# STM32F407 register map
File version: 1.7
CPU: CM4 r0p1, little endian, MPU, FPU, 4 interrupt priority bits
Registers are 32-bit, read-write, reset 0x0 unless marked. A register's access mark holds for its fields unless they carry their own. Offsets are from the block's base; [hi:lo] are bit positions; {n}, {i} and the like mark numbered series.

## OTG_FS_PWRCLK — USB on the go full speed
Base 0x50000E00
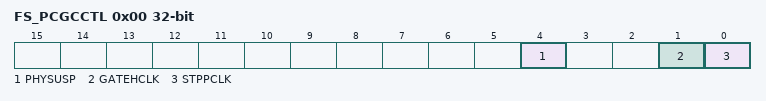
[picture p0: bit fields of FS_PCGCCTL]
0x00 FS_PCGCCTL — OTG_FS power and clock gating control register
  [4] PHYSUSP — PHY Suspended
  [1] GATEHCLK
  [0] STPPCLK — Stop PHY clock

## FLASH
Base 0x40023C00
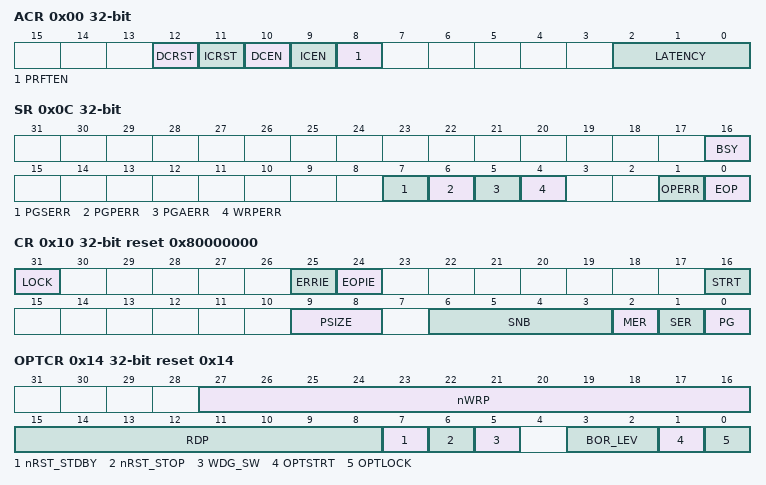
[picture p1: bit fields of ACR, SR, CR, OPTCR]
0x00 ACR access per field — Flash access control register
  [12] DCRST rw — Data cache reset
  [11] ICRST wo — Instruction cache reset
  [10] DCEN rw — Data cache enable
  [9] ICEN rw — Instruction cache enable
  [8] PRFTEN rw — Prefetch enable
  [2:0] LATENCY rw
0x04 KEYR wo — Flash key register
  [31:0] KEY — FPEC key
0x08 OPTKEYR wo — Flash option key register
  [31:0] OPTKEY — Option byte key
0x0C SR access per field — Status register
  [16] BSY ro — Busy
  [7] PGSERR rw — Programming sequence error
  [6] PGPERR rw — Programming parallelism error
  [5] PGAERR rw — Programming alignment error
  [4] WRPERR rw — Write protection error
  [1] OPERR rw — Operation error
  [0] EOP rw — End of operation
0x10 CR reset 0x80000000 — Control register
  [31] LOCK
  [25] ERRIE — Error interrupt enable
  [24] EOPIE — End of operation interrupt enable
  [16] STRT — Start
  [9:8] PSIZE — Program size
  [6:3] SNB — Sector number
  [2] MER — Mass Erase
  [1] SER — Sector Erase
  [0] PG — Programming
0x14 OPTCR reset 0x14 — Flash option control register
  [27:16] nWRP — Not write protect
  [15:8] RDP — Read protect
  [7] nRST_STDBY — nRST_STDBY User option bytes
  [6] nRST_STOP — nRST_STOP User option bytes
  [5] WDG_SW — WDG_SW User option bytes
  [3:2] BOR_LEV — BOR reset Level
  [1] OPTSTRT — Option start
  [0] OPTLOCK — Option lock

## EXTI — External interrupt/event controller
Base 0x40013C00
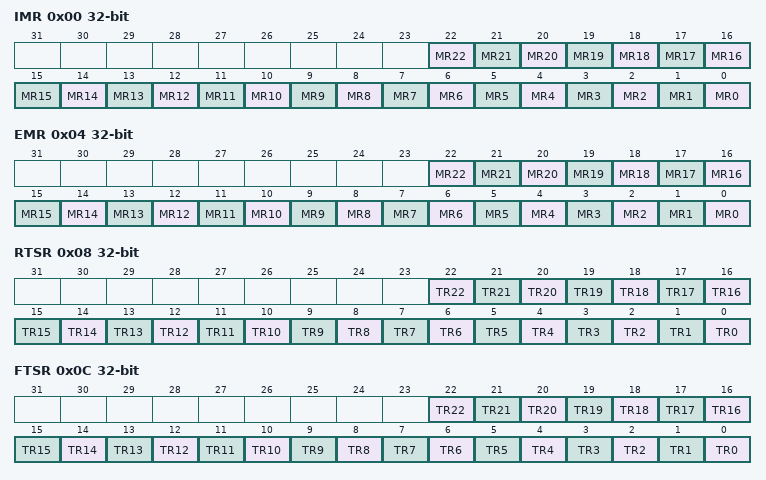
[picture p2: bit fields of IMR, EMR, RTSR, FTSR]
0x00 IMR — Interrupt mask register (EXTI_IMR)
  [n] MR{n} (n=0..22) — Interrupt Mask on line {n}
0x04 EMR — Event mask register (EXTI_EMR)
  [n] MR{n} (n=0..22) — Event Mask on line {n}
0x08 RTSR — Rising Trigger selection register (EXTI_RTSR)
  [n] TR{n} (n=0..22) — Rising trigger event configuration of line {n}
0x0C FTSR — Falling Trigger selection register (EXTI_FTSR)
  [n] TR{n} (n=0..22) — Falling trigger event configuration of line {n}
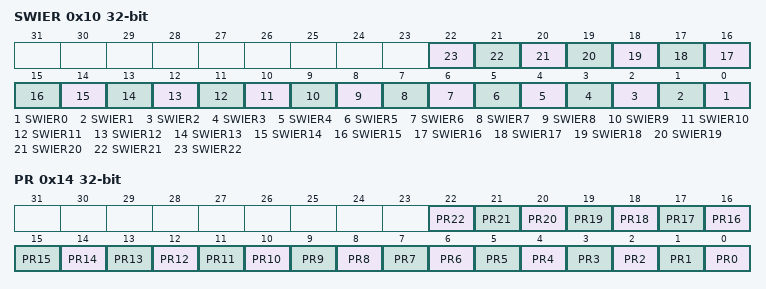
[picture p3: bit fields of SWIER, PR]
0x10 SWIER — Software interrupt event register (EXTI_SWIER)
  [n] SWIER{n} (n=0..22) — Software Interrupt on line {n}
0x14 PR — Pending register (EXTI_PR)
  [n] PR{n} (n=0..22) — Pending bit {n}

## OTG_HS_PWRCLK — USB on the go high speed
Base 0x40040E00
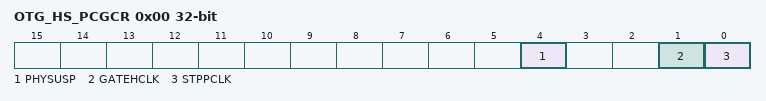
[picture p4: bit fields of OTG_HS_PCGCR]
0x00 OTG_HS_PCGCR — Power and clock gating control register
  [4] PHYSUSP — PHY suspended
  [1] GATEHCLK
  [0] STPPCLK — Stop PHY clock

## HASH — Hash processor
Base 0x50060400
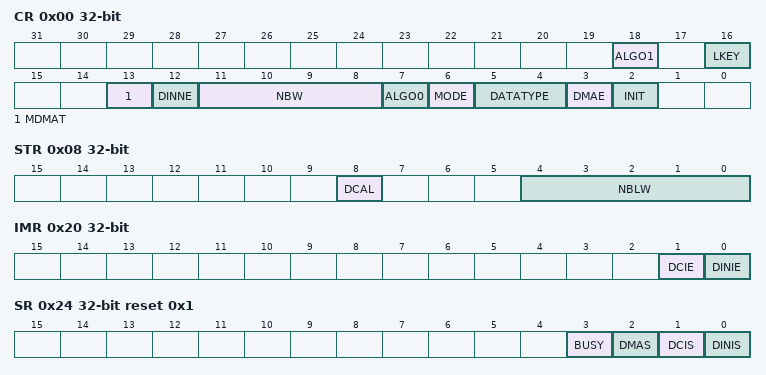
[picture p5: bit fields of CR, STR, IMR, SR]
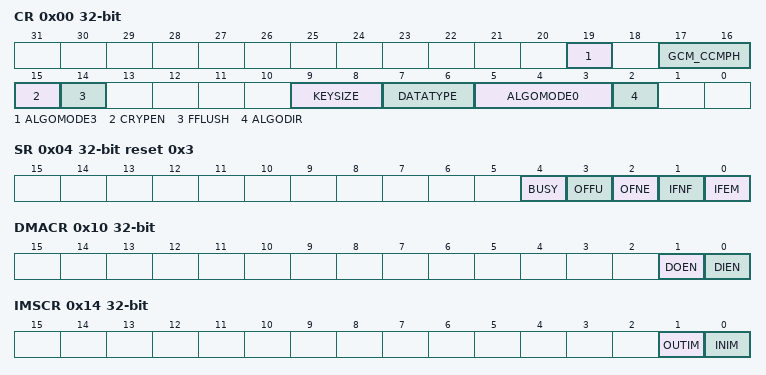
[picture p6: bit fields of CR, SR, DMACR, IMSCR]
0x00 CR access per field — control register
  [18] ALGO1 rw — ALGO
  [16] LKEY rw — Long key selection
  [13] MDMAT rw — Multiple DMA Transfers
  [12] DINNE ro — DIN not empty
  [11:8] NBW ro — Number of words already pushed
  [7] ALGO0 rw — Algorithm selection
  [6] MODE rw — Mode selection
  [5:4] DATATYPE rw — Data type selection
  [3] DMAE rw — DMA enable
  [2] INIT wo — Initialize message digest calculation
0x04 DIN — data input register
  [31:0] DATAIN — Data input
0x08 STR access per field — start register
  [8] DCAL wo — Digest calculation
  [4:0] NBLW rw — Number of valid bits in the last word of the message
{0xC+4i} HR{i} ro (i=0..4) — digest registers
  [31:0] H{i}
0x20 IMR — interrupt enable register
  [1] DCIE — Digest calculation completion interrupt enable
  [0] DINIE — Data input interrupt enable
0x24 SR access per field reset 0x1 — status register
  [3] BUSY ro — Busy bit
  [2] DMAS ro — DMA Status
  [1] DCIS rw — Digest calculation completion interrupt status
  [0] DINIS rw — Data input interrupt status
{0xF8+4i} CSR{i} (i=0..53) — context swap registers
0x310 HASH_HR0 ro — HASH digest register
  [31:0] H0
{0x310+4i} HASH_HR{i} ro (i=1..7) — read-only
  [31:0] H{i}

## CRYP — Cryptographic processor
Base 0x50060000
0x00 CR access per field — control register
  [19] ALGOMODE3 rw — ALGOMODE
  [17:16] GCM_CCMPH rw
  [15] CRYPEN rw — Cryptographic processor enable
  [14] FFLUSH wo — FIFO flush
  [9:8] KEYSIZE rw — Key size selection (AES mode only)
  [7:6] DATATYPE rw — Data type selection
  [5:3] ALGOMODE0 rw — Algorithm mode
  [2] ALGODIR rw — Algorithm direction
0x04 SR ro reset 0x3 — status register
  [4] BUSY — Busy bit
  [3] OFFU — Output FIFO full
  [2] OFNE — Output FIFO not empty
  [1] IFNF — Input FIFO not full
  [0] IFEM — Input FIFO empty
0x08 DIN — data input register
  [31:0] DATAIN — Data input
0x0C DOUT ro — data output register
  [31:0] DATAOUT — Data output
0x10 DMACR — DMA control register
  [1] DOEN — DMA output enable
  [0] DIEN — DMA input enable
0x14 IMSCR — interrupt mask set/clear register
  [1] OUTIM — Output FIFO service interrupt mask
  [0] INIM — Input FIFO service interrupt mask
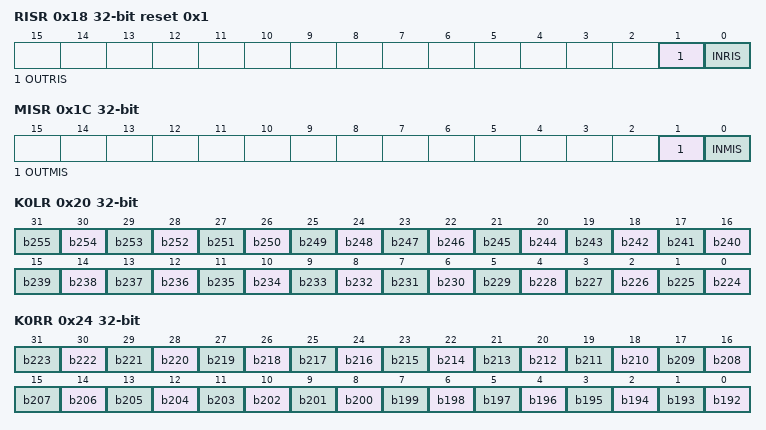
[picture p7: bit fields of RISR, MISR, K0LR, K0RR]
0x18 RISR ro reset 0x1 — raw interrupt status register
  [1] OUTRIS — Output FIFO service raw interrupt status
  [0] INRIS — Input FIFO service raw interrupt status
0x1C MISR ro — masked interrupt status register
  [1] OUTMIS — Output FIFO service masked interrupt status
  [0] INMIS — Input FIFO service masked interrupt status
0x20 K0LR wo — key registers
  [n-224] b{n} (n=224..255)
0x24 K0RR wo — key registers
  [n-192] b{n} (n=192..223)
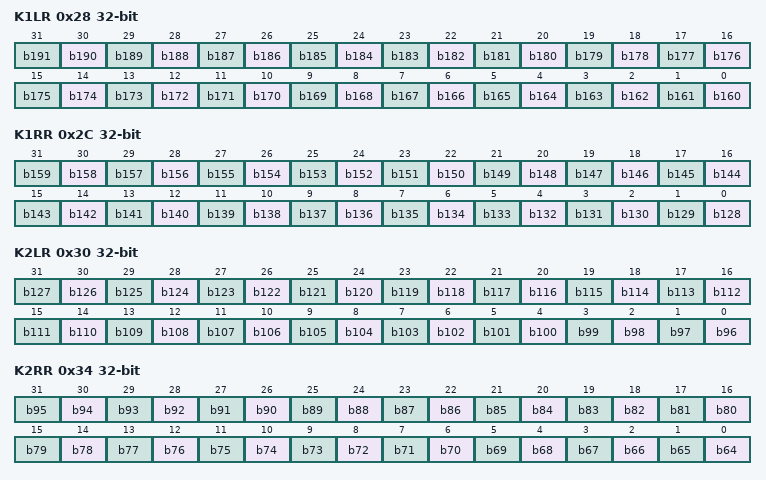
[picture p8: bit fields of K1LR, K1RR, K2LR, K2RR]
0x28 K1LR wo — key registers
  [n-160] b{n} (n=160..191)
0x2C K1RR wo — key registers
  [n-128] b{n} (n=128..159)
0x30 K2LR wo — key registers
  [n-96] b{n} (n=96..127)
0x34 K2RR wo — key registers
  [n-64] b{n} (n=64..95)
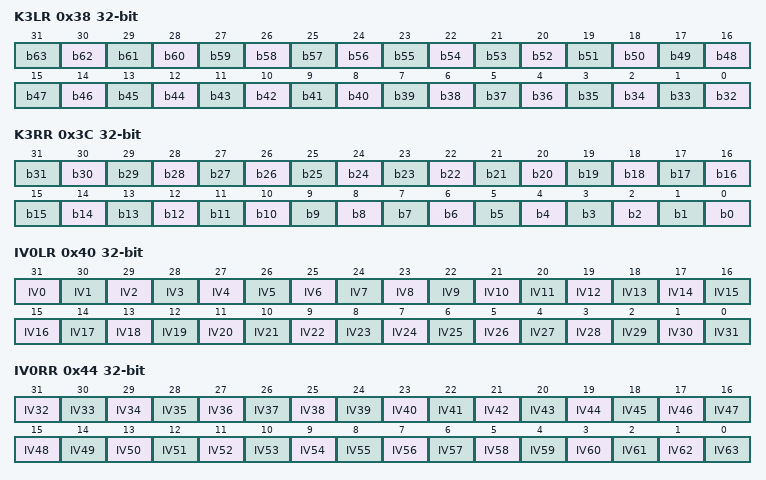
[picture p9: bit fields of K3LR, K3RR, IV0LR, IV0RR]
0x38 K3LR wo — key registers
  [n-32] b{n} (n=32..63)
0x3C K3RR wo — key registers
  [n] b{n} (n=0..31)
0x40 IV0LR — initialization vector registers
  [31-n] IV{n} (n=0..31)
0x44 IV0RR — initialization vector registers
  [63-n] IV{n} (n=32..63)
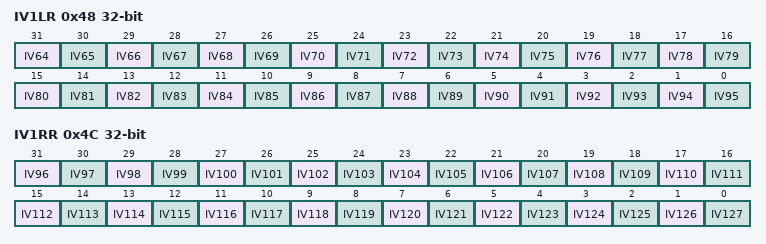
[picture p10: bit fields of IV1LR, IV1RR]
0x48 IV1LR — initialization vector registers
  [95-n] IV{n} (n=64..95)
0x4C IV1RR — initialization vector registers
  [127-n] IV{n} (n=96..127)
{0x50+4i} CSGCMCCM{i}R (i=0..7) — context swap register
{0x70+4i} CSGCM{i}R (i=0..7) — context swap register

## Notices in the file
Copyright (c) 2024 STMicroelectronics.
SPDX-License-Identifier: Apache-2.0
Licensed under the Apache License, Version 2.0 (the "License");
you may not use this file except in compliance with the License.
You may obtain a copy of the License at
http://www.apache.org/licenses/LICENSE-2.0
Unless required by applicable law or agreed to in writing, software
distributed under the License is distributed on an "AS IS" BASIS,
WITHOUT WARRANTIES OR CONDITIONS OF ANY KIND, either express or implied.
See the License for the specific language governing permissions and
limitations under the License.
